VERSION "1.0"

NS_ :

BS_:

BU_: Engine Battery Gateway

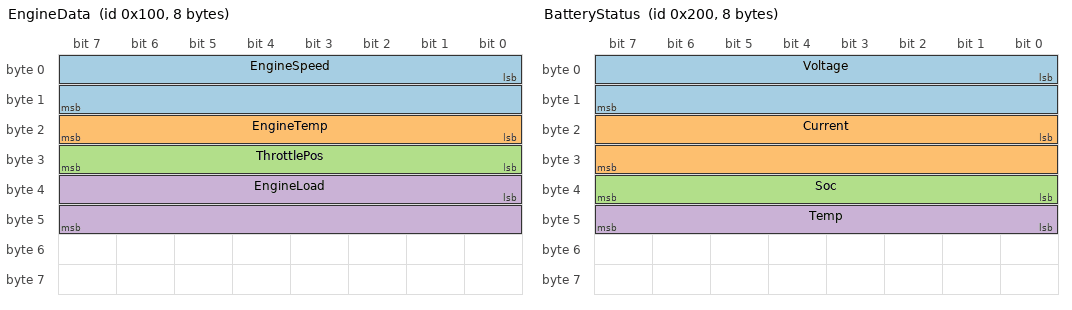
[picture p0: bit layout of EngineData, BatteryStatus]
BO_ 256 EngineData: 8 Gateway
 SG_ EngineSpeed : 0|16@1+ (0.25,0) [0|16383.75] "rpm" Gateway
 SG_ EngineTemp : 16|8@1+ (1,-40) [-40|215] "degC" Gateway
 SG_ ThrottlePos : 24|8@1+ (0.4,0) [0|100] "%" Gateway
 SG_ EngineLoad : 32|16@1+ (0.001,0) [0|65.535] "%" Gateway

BO_ 512 BatteryStatus: 8 Gateway
 SG_ Voltage : 0|16@1+ (0.001,0) [0|65.535] "V" Gateway
 SG_ Current : 16|16@1- (0.1,0) [-3276.8|3276.7] "A" Gateway
 SG_ Soc : 32|8@1+ (0.5,0) [0|100] "%" Gateway
 SG_ Temp : 40|8@1+ (1,-40) [-40|215] "degC" Gateway

BO_ 770 Status: 4 Gateway
 SG_ Gear : 0|4@1+ (1,0) [0|15] "" Gateway
 SG_ MotorSpeed : 8|16@0+ (1,0) [0|65535] "rpm" Gateway
